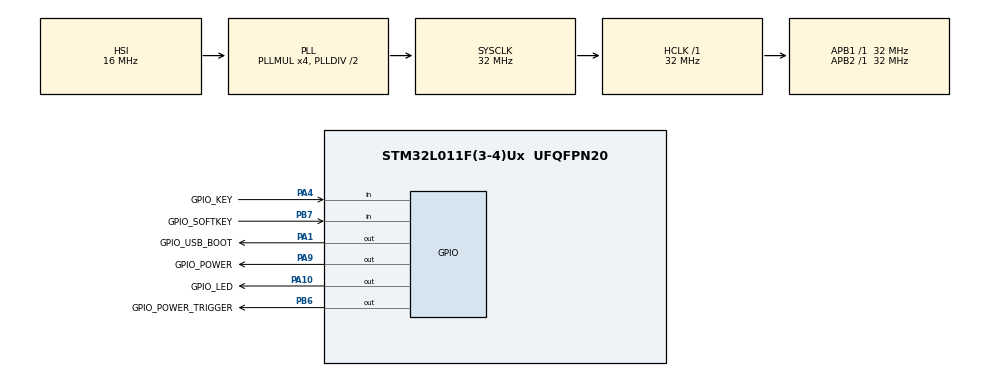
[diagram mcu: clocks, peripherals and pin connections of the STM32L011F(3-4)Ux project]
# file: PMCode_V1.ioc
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Mcu.Family=STM32L0
Mcu.Name=STM32L011F(3-4)Ux
Mcu.Package=UFQFPN20
NVIC.TIM2_IRQn=true\:0\:0\:true\:false\:true\:false\:true
NVIC.TimeBase=TIM2_IRQn
NVIC.TimeBaseIP=TIM2
PA1.GPIO_Label=GPIO_USB_BOOT
PA1.Signal=GPIO_Output
PA10.GPIO_Label=GPIO_LED
PA10.Signal=GPIO_Output
PA13.Mode=Serial_Wire
PA13.Signal=SYS_SWDIO
PA14.Mode=Serial_Wire
PA14.Signal=SYS_SWCLK
PA4.GPIO_Label=GPIO_KEY
PA4.Signal=GPIO_Input
PA9.GPIO_Label=GPIO_POWER
PA9.PinState=GPIO_PIN_RESET
PA9.Signal=GPIO_Output
PB6.GPIO_Label=GPIO_POWER_TRIGGER
PB6.GPIO_PuPd=GPIO_PULLDOWN
PB6.Signal=GPIO_Output
PB7.GPIO_Label=GPIO_SOFTKEY
PB7.Signal=GPIO_Input
ProjectManager.HeapSize=0x200
ProjectManager.StackSize=0x400
ProjectManager.TargetToolchain=MDK-ARM V5
RCC.AHBFreq_Value=32000000
RCC.APB1Freq_Value=32000000
RCC.APB1TimFreq_Value=32000000
RCC.APB2Freq_Value=32000000
RCC.APB2TimFreq_Value=32000000
RCC.HCLKFreq_Value=32000000
RCC.HSE_VALUE=8000000
RCC.HSI16_VALUE=16000000
RCC.HSI_VALUE=16000000
RCC.LSE_VALUE=32768
RCC.MSI_VALUE=2097000
RCC.PLLMUL=RCC_PLLMUL_4
RCC.SYSCLKFreq_VALUE=32000000
RCC.SYSCLKSource=RCC_SYSCLKSOURCE_PLLCLK
RCC.VCOOutputFreq_Value=64000000
VP_SYS_VS_tim2.Mode=TIM2
board=custom

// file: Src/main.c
/* USER CODE BEGIN Header */
/**
  ******************************************************************************
  * @file           : main.c
  * @brief          : Main program body
  ******************************************************************************
  ** This notice applies to any and all portions of this file
  * that are not between comment pairs USER CODE BEGIN and
  * USER CODE END. Other portions of this file, whether
  * inserted by the user or by software development tools
  * are owned by their respective copyright owners.
  *
  * COPYRIGHT(c) 2020 STMicroelectronics
  *
  * Redistribution and use in source and binary forms, with or without modification,
  * are permitted provided that the following conditions are met:
  *   1. Redistributions of source code must retain the above copyright notice,
  *      this list of conditions and the following disclaimer.
  *   2. Redistributions in binary form must reproduce the above copyright notice,
  *      this list of conditions and the following disclaimer in the documentation
  *      and/or other materials provided with the distribution.
  *   3. Neither the name of STMicroelectronics nor the names of its contributors
  *      may be used to endorse or promote products derived from this software
  *      without specific prior written permission.
  *
  * THIS SOFTWARE IS PROVIDED BY THE COPYRIGHT HOLDERS AND CONTRIBUTORS "AS IS"
  * AND ANY EXPRESS OR IMPLIED WARRANTIES, INCLUDING, BUT NOT LIMITED TO, THE
  * IMPLIED WARRANTIES OF MERCHANTABILITY AND FITNESS FOR A PARTICULAR PURPOSE ARE
  * DISCLAIMED. IN NO EVENT SHALL THE COPYRIGHT HOLDER OR CONTRIBUTORS BE LIABLE
  * FOR ANY DIRECT, INDIRECT, INCIDENTAL, SPECIAL, EXEMPLARY, OR CONSEQUENTIAL
  * DAMAGES (INCLUDING, BUT NOT LIMITED TO, PROCUREMENT OF SUBSTITUTE GOODS OR
  * SERVICES; LOSS OF USE, DATA, OR PROFITS; OR BUSINESS INTERRUPTION) HOWEVER
  * CAUSED AND ON ANY THEORY OF LIABILITY, WHETHER IN CONTRACT, STRICT LIABILITY,
  * OR TORT (INCLUDING NEGLIGENCE OR OTHERWISE) ARISING IN ANY WAY OUT OF THE USE
  * OF THIS SOFTWARE, EVEN IF ADVISED OF THE POSSIBILITY OF SUCH DAMAGE.
  *
  ******************************************************************************
  */
/* USER CODE END Header */

#include "main.h"

/* USER CODE BEGIN Includes */
#include "userapp.h"

/* USER CODE END Includes */

void SystemClock_Config(void);
static void MX_GPIO_Init(void);

int main(void)
{

  /* MCU Configuration--------------------------------------------------------*/

  /* Reset of all peripherals, Initializes the Flash interface and the Systick. */
  HAL_Init();

  /* Configure the system clock */
  SystemClock_Config();

  /* Initialize all configured peripherals */
  MX_GPIO_Init();
  /* USER CODE BEGIN 2 */
	PowerManagerInit();

  /* USER CODE END 2 */

  /* Infinite loop */
  while (1)
  {

    /* USER CODE BEGIN 3 */
		PowerManager();
  }
  /* USER CODE END 3 */
}

void SystemClock_Config(void)
{
  RCC_OscInitTypeDef RCC_OscInitStruct = {0};
  RCC_ClkInitTypeDef RCC_ClkInitStruct = {0};

  /**Configure the main internal regulator output voltage
  */
  __HAL_PWR_VOLTAGESCALING_CONFIG(PWR_REGULATOR_VOLTAGE_SCALE1);
  /**Initializes the CPU, AHB and APB busses clocks
  */
  RCC_OscInitStruct.OscillatorType = RCC_OSCILLATORTYPE_HSI;
  RCC_OscInitStruct.HSIState = RCC_HSI_ON;
  RCC_OscInitStruct.HSICalibrationValue = RCC_HSICALIBRATION_DEFAULT;
  RCC_OscInitStruct.PLL.PLLState = RCC_PLL_ON;
  RCC_OscInitStruct.PLL.PLLSource = RCC_PLLSOURCE_HSI;
  RCC_OscInitStruct.PLL.PLLMUL = RCC_PLLMUL_4;
  RCC_OscInitStruct.PLL.PLLDIV = RCC_PLLDIV_2;
  if (HAL_RCC_OscConfig(&RCC_OscInitStruct) != HAL_OK)
  {
    Error_Handler();
  }
  /**Initializes the CPU, AHB and APB busses clocks
  */
  RCC_ClkInitStruct.ClockType = RCC_CLOCKTYPE_HCLK|RCC_CLOCKTYPE_SYSCLK
                              |RCC_CLOCKTYPE_PCLK1|RCC_CLOCKTYPE_PCLK2;
  RCC_ClkInitStruct.SYSCLKSource = RCC_SYSCLKSOURCE_PLLCLK;
  RCC_ClkInitStruct.AHBCLKDivider = RCC_SYSCLK_DIV1;
  RCC_ClkInitStruct.APB1CLKDivider = RCC_HCLK_DIV1;
  RCC_ClkInitStruct.APB2CLKDivider = RCC_HCLK_DIV1;

  if (HAL_RCC_ClockConfig(&RCC_ClkInitStruct, FLASH_LATENCY_1) != HAL_OK)
  {
    Error_Handler();
  }
}

static void MX_GPIO_Init(void)
{
  GPIO_InitTypeDef GPIO_InitStruct = {0};

  /* GPIO Ports Clock Enable */
  __HAL_RCC_GPIOA_CLK_ENABLE();
  __HAL_RCC_GPIOB_CLK_ENABLE();

  /*Configure GPIO pin Output Level */
  HAL_GPIO_WritePin(GPIOA, GPIO_USB_BOOT_Pin|GPIO_POWER_Pin|GPIO_LED_Pin, GPIO_PIN_RESET);

  /*Configure GPIO pin Output Level */
  HAL_GPIO_WritePin(GPIO_POWER_TRIGGER_GPIO_Port, GPIO_POWER_TRIGGER_Pin, GPIO_PIN_RESET);

  /*Configure GPIO pins : GPIO_USB_BOOT_Pin GPIO_POWER_Pin GPIO_LED_Pin */
  GPIO_InitStruct.Pin = GPIO_USB_BOOT_Pin|GPIO_POWER_Pin|GPIO_LED_Pin;
  GPIO_InitStruct.Mode = GPIO_MODE_OUTPUT_PP;
  GPIO_InitStruct.Pull = GPIO_NOPULL;
  GPIO_InitStruct.Speed = GPIO_SPEED_FREQ_LOW;
  HAL_GPIO_Init(GPIOA, &GPIO_InitStruct);

  /*Configure GPIO pin : GPIO_KEY_Pin */
  GPIO_InitStruct.Pin = GPIO_KEY_Pin;
  GPIO_InitStruct.Mode = GPIO_MODE_INPUT;
  GPIO_InitStruct.Pull = GPIO_NOPULL;
  HAL_GPIO_Init(GPIO_KEY_GPIO_Port, &GPIO_InitStruct);

  /*Configure GPIO pin : GPIO_POWER_TRIGGER_Pin */
  GPIO_InitStruct.Pin = GPIO_POWER_TRIGGER_Pin;
  GPIO_InitStruct.Mode = GPIO_MODE_OUTPUT_PP;
  GPIO_InitStruct.Pull = GPIO_PULLDOWN;
  GPIO_InitStruct.Speed = GPIO_SPEED_FREQ_LOW;
  HAL_GPIO_Init(GPIO_POWER_TRIGGER_GPIO_Port, &GPIO_InitStruct);

  /*Configure GPIO pin : GPIO_SOFTKEY_Pin */
  GPIO_InitStruct.Pin = GPIO_SOFTKEY_Pin;
  GPIO_InitStruct.Mode = GPIO_MODE_INPUT;
  GPIO_InitStruct.Pull = GPIO_NOPULL;
  HAL_GPIO_Init(GPIO_SOFTKEY_GPIO_Port, &GPIO_InitStruct);

}

void HAL_TIM_PeriodElapsedCallback(TIM_HandleTypeDef *htim)
{
  if (htim->Instance == TIM2) {
    HAL_IncTick();
  }
}

void Error_Handler(void)
{
}

/************************ (C) COPYRIGHT STMicroelectronics *****END OF FILE****/
